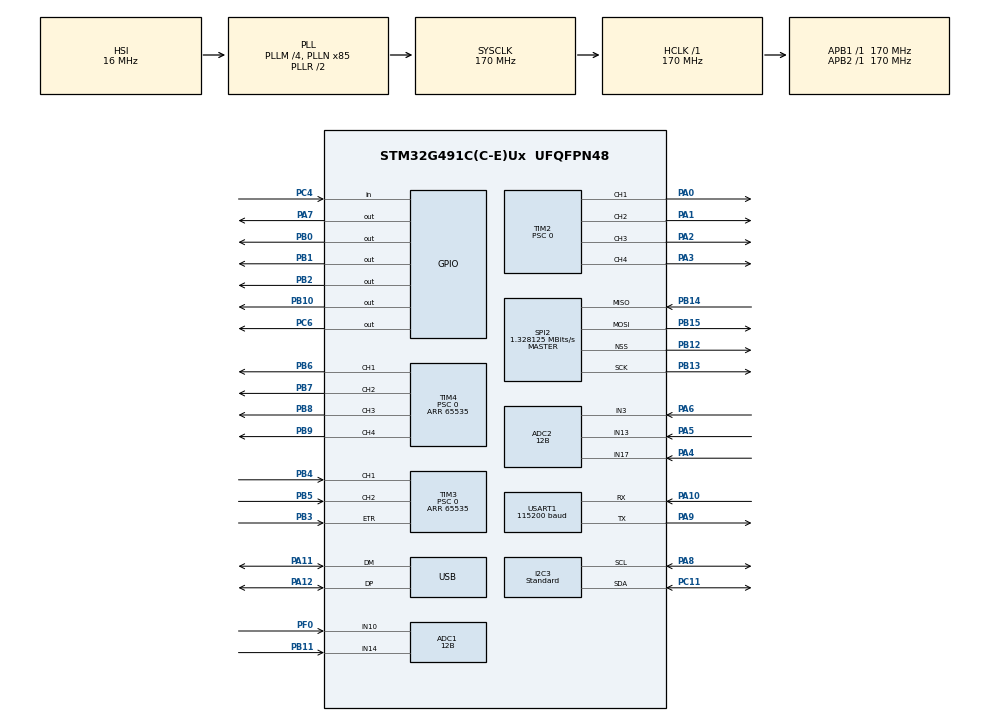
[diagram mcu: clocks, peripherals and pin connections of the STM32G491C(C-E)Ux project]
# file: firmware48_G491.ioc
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ADC1.Channel-0\#ChannelRegularConversion=ADC_CHANNEL_14
ADC1.Channel-1\#ChannelRegularConversion=ADC_CHANNEL_TEMPSENSOR_ADC1
ADC1.Channel-2\#ChannelRegularConversion=ADC_CHANNEL_VBAT
ADC1.Channel-3\#ChannelRegularConversion=ADC_CHANNEL_VREFINT
ADC1.Channel-4\#ChannelRegularConversion=ADC_CHANNEL_10
ADC1.Channel-IN=ADC_CHANNEL_VREFINT
ADC1.Channel-IN10=ADC_CHANNEL_10
ADC1.Channel-IN14=ADC_CHANNEL_14
ADC1.ClockPrescaler=ADC_CLOCK_ASYNC_DIV2
ADC1.ContinuousConvMode=ENABLE
ADC1.DMAContinuousRequests=ENABLE
ADC1.DataAlign=ADC_DATAALIGN_RIGHT
ADC1.DiscontinuousConvMode=DISABLE
ADC1.EOCSelection=ADC_EOC_SEQ_CONV
ADC1.EnableAnalogWatchDog1=false
ADC1.EnableAnalogWatchDog2=false
ADC1.EnableAnalogWatchDog3=false
ADC1.EnableInjectedConversion=DISABLE
ADC1.EnableRegularConversion=ENABLE
ADC1.ExternalTrigConv=ADC_SOFTWARE_START
ADC1.ExternalTrigConvEdge=ADC_EXTERNALTRIGCONVEDGE_NONE
ADC1.GainCompensation=0
ADC1.LowPowerAutoWait=DISABLE
ADC1.Mode=ADC_MODE_INDEPENDENT
ADC1.NbrOfConversion=5
ADC1.OffsetNumber-0\#ChannelRegularConversion=ADC_OFFSET_NONE
ADC1.OffsetNumber-1\#ChannelRegularConversion=ADC_OFFSET_NONE
ADC1.OffsetNumber-2\#ChannelRegularConversion=ADC_OFFSET_NONE
ADC1.OffsetNumber-3\#ChannelRegularConversion=ADC_OFFSET_NONE
ADC1.OffsetNumber-4\#ChannelRegularConversion=ADC_OFFSET_NONE
ADC1.Overrun=ADC_OVR_DATA_OVERWRITTEN
ADC1.OversamplingMode=ENABLE
ADC1.OversamplingStopReset=ADC_REGOVERSAMPLING_CONTINUED_MODE
ADC1.Rank-0\#ChannelRegularConversion=1
ADC1.Rank-1\#ChannelRegularConversion=2
ADC1.Rank-2\#ChannelRegularConversion=3
ADC1.Rank-3\#ChannelRegularConversion=4
ADC1.Rank-4\#ChannelRegularConversion=5
ADC1.Ratio=ADC_OVERSAMPLING_RATIO_256
ADC1.Resolution=ADC_RESOLUTION_12B
ADC1.RightBitShift=ADC_RIGHTBITSHIFT_4
ADC1.SamplingTime-0\#ChannelRegularConversion=ADC_SAMPLETIME_640CYCLES_5
ADC1.SamplingTime-1\#ChannelRegularConversion=ADC_SAMPLETIME_640CYCLES_5
ADC1.SamplingTime-2\#ChannelRegularConversion=ADC_SAMPLETIME_640CYCLES_5
ADC1.SamplingTime-3\#ChannelRegularConversion=ADC_SAMPLETIME_640CYCLES_5
ADC1.SamplingTime-4\#ChannelRegularConversion=ADC_SAMPLETIME_640CYCLES_5
ADC1.ScanConvMode=ADC_SCAN_ENABLE
ADC1.TriggeredMode=ADC_TRIGGEREDMODE_SINGLE_TRIGGER
ADC1.master=1
ADC2.Channel-0\#ChannelRegularConversion=ADC_CHANNEL_17
ADC2.Channel-1\#ChannelRegularConversion=ADC_CHANNEL_17
ADC2.Channel-2\#ChannelRegularConversion=ADC_CHANNEL_13
ADC2.Channel-3\#ChannelRegularConversion=ADC_CHANNEL_13
ADC2.Channel-4\#ChannelRegularConversion=ADC_CHANNEL_3
ADC2.Channel-5\#ChannelRegularConversion=ADC_CHANNEL_3
ADC2.Channel-IN13=ADC_CHANNEL_13
ADC2.Channel-IN17=ADC_CHANNEL_17
ADC2.Channel-IN3=ADC_CHANNEL_3
ADC2.ClockPrescaler=ADC_CLOCK_ASYNC_DIV2
ADC2.ContinuousConvMode=DISABLE
ADC2.DMAContinuousRequests=ENABLE
ADC2.DataAlign=ADC_DATAALIGN_RIGHT
ADC2.DiscontinuousConvMode=ENABLE
ADC2.EOCSelection=ADC_EOC_SEQ_CONV
ADC2.EnableAnalogWatchDog1=false
ADC2.EnableAnalogWatchDog2=false
ADC2.EnableAnalogWatchDog3=false
ADC2.EnableInjectedConversion=DISABLE
ADC2.EnableRegularConversion=ENABLE
ADC2.ExternalTrigConv=ADC_EXTERNALTRIG_T15_TRGO
ADC2.ExternalTrigConvEdge=ADC_EXTERNALTRIGCONVEDGE_RISING
ADC2.GainCompensation=0
ADC2.LowPowerAutoWait=DISABLE
ADC2.Mode=ADC_MODE_INDEPENDENT
ADC2.NbrOfConversion=6
ADC2.NbrOfDiscConversion=1
ADC2.OffsetNumber-0\#ChannelRegularConversion=ADC_OFFSET_NONE
ADC2.OffsetNumber-1\#ChannelRegularConversion=ADC_OFFSET_NONE
ADC2.OffsetNumber-2\#ChannelRegularConversion=ADC_OFFSET_NONE
ADC2.OffsetNumber-3\#ChannelRegularConversion=ADC_OFFSET_NONE
ADC2.OffsetNumber-4\#ChannelRegularConversion=ADC_OFFSET_NONE
ADC2.OffsetNumber-5\#ChannelRegularConversion=ADC_OFFSET_NONE
ADC2.Overrun=ADC_OVR_DATA_OVERWRITTEN
ADC2.OversamplingMode=ENABLE
ADC2.OversamplingStopReset=ADC_REGOVERSAMPLING_CONTINUED_MODE
ADC2.Rank-0\#ChannelRegularConversion=1
ADC2.Rank-1\#ChannelRegularConversion=2
ADC2.Rank-2\#ChannelRegularConversion=3
ADC2.Rank-3\#ChannelRegularConversion=4
ADC2.Rank-4\#ChannelRegularConversion=5
ADC2.Rank-5\#ChannelRegularConversion=6
ADC2.Ratio=ADC_OVERSAMPLING_RATIO_16
ADC2.Resolution=ADC_RESOLUTION_12B
ADC2.RightBitShift=ADC_RIGHTBITSHIFT_NONE
ADC2.SamplingTime-0\#ChannelRegularConversion=ADC_SAMPLETIME_12CYCLES_5
ADC2.SamplingTime-1\#ChannelRegularConversion=ADC_SAMPLETIME_12CYCLES_5
ADC2.SamplingTime-2\#ChannelRegularConversion=ADC_SAMPLETIME_12CYCLES_5
ADC2.SamplingTime-3\#ChannelRegularConversion=ADC_SAMPLETIME_12CYCLES_5
ADC2.SamplingTime-4\#ChannelRegularConversion=ADC_SAMPLETIME_12CYCLES_5
ADC2.SamplingTime-5\#ChannelRegularConversion=ADC_SAMPLETIME_12CYCLES_5
ADC2.ScanConvMode=ADC_SCAN_ENABLE
ADC2.TriggeredMode=ADC_TRIGGEREDMODE_SINGLE_TRIGGER
Dma.ADC1.3.Direction=DMA_PERIPH_TO_MEMORY
Dma.ADC1.3.EventEnable=DISABLE
Dma.ADC1.3.Instance=DMA1_Channel1
Dma.ADC1.3.MemDataAlignment=DMA_MDATAALIGN_HALFWORD
Dma.ADC1.3.MemInc=DMA_MINC_ENABLE
Dma.ADC1.3.Mode=DMA_CIRCULAR
Dma.ADC1.3.PeriphDataAlignment=DMA_PDATAALIGN_HALFWORD
Dma.ADC1.3.PeriphInc=DMA_PINC_DISABLE
Dma.ADC1.3.Polarity=HAL_DMAMUX_REQ_GEN_RISING
Dma.ADC1.3.Priority=DMA_PRIORITY_LOW
Dma.ADC1.3.RequestNumber=1
Dma.ADC1.3.SignalID=NONE
Dma.ADC1.3.SyncEnable=DISABLE
Dma.ADC1.3.SyncPolarity=HAL_DMAMUX_SYNC_NO_EVENT
Dma.ADC1.3.SyncRequestNumber=1
Dma.ADC1.3.SyncSignalID=NONE
Dma.ADC2.2.Direction=DMA_PERIPH_TO_MEMORY
Dma.ADC2.2.EventEnable=DISABLE
Dma.ADC2.2.Instance=DMA1_Channel2
Dma.ADC2.2.MemDataAlignment=DMA_MDATAALIGN_HALFWORD
Dma.ADC2.2.MemInc=DMA_MINC_ENABLE
Dma.ADC2.2.Mode=DMA_CIRCULAR
Dma.ADC2.2.PeriphDataAlignment=DMA_PDATAALIGN_HALFWORD
Dma.ADC2.2.PeriphInc=DMA_PINC_DISABLE
Dma.ADC2.2.Polarity=HAL_DMAMUX_REQ_GEN_RISING
Dma.ADC2.2.Priority=DMA_PRIORITY_HIGH
Dma.ADC2.2.RequestNumber=1
Dma.ADC2.2.SignalID=NONE
Dma.ADC2.2.SyncEnable=DISABLE
Dma.ADC2.2.SyncPolarity=HAL_DMAMUX_SYNC_NO_EVENT
Dma.ADC2.2.SyncRequestNumber=1
Dma.ADC2.2.SyncSignalID=NONE
Dma.Request0=SPI2_RX
Dma.Request1=SPI2_TX
Dma.Request2=ADC2
Dma.Request3=ADC1
Dma.SPI2_RX.0.Direction=DMA_PERIPH_TO_MEMORY
Dma.SPI2_RX.0.EventEnable=DISABLE
Dma.SPI2_RX.0.Instance=DMA2_Channel1
Dma.SPI2_RX.0.MemDataAlignment=DMA_MDATAALIGN_HALFWORD
Dma.SPI2_RX.0.MemInc=DMA_MINC_ENABLE
Dma.SPI2_RX.0.Mode=DMA_NORMAL
Dma.SPI2_RX.0.PeriphDataAlignment=DMA_PDATAALIGN_HALFWORD
Dma.SPI2_RX.0.PeriphInc=DMA_PINC_DISABLE
Dma.SPI2_RX.0.Polarity=HAL_DMAMUX_REQ_GEN_RISING
Dma.SPI2_RX.0.Priority=DMA_PRIORITY_LOW
Dma.SPI2_RX.0.RequestNumber=1
Dma.SPI2_RX.0.SignalID=NONE
Dma.SPI2_RX.0.SyncEnable=DISABLE
Dma.SPI2_RX.0.SyncPolarity=HAL_DMAMUX_SYNC_NO_EVENT
Dma.SPI2_RX.0.SyncRequestNumber=1
Dma.SPI2_RX.0.SyncSignalID=NONE
Dma.SPI2_TX.1.Direction=DMA_MEMORY_TO_PERIPH
Dma.SPI2_TX.1.EventEnable=DISABLE
Dma.SPI2_TX.1.Instance=DMA2_Channel2
Dma.SPI2_TX.1.MemDataAlignment=DMA_MDATAALIGN_HALFWORD
Dma.SPI2_TX.1.MemInc=DMA_MINC_ENABLE
Dma.SPI2_TX.1.Mode=DMA_NORMAL
Dma.SPI2_TX.1.PeriphDataAlignment=DMA_PDATAALIGN_HALFWORD
Dma.SPI2_TX.1.PeriphInc=DMA_PINC_DISABLE
Dma.SPI2_TX.1.Polarity=HAL_DMAMUX_REQ_GEN_RISING
Dma.SPI2_TX.1.Priority=DMA_PRIORITY_LOW
Dma.SPI2_TX.1.RequestNumber=1
Dma.SPI2_TX.1.SignalID=NONE
Dma.SPI2_TX.1.SyncEnable=DISABLE
Dma.SPI2_TX.1.SyncPolarity=HAL_DMAMUX_SYNC_NO_EVENT
Dma.SPI2_TX.1.SyncRequestNumber=1
Dma.SPI2_TX.1.SyncSignalID=NONE
I2C3.AddressingMode=I2C_ADDRESSINGMODE_7BIT
I2C3.Analog_Filter=I2C_ANALOGFILTER_ENABLE
I2C3.CustomTiming=Disabled
I2C3.DualAddressMode=I2C_DUALADDRESS_DISABLE
I2C3.GeneralCallMode=I2C_GENERALCALL_DISABLE
I2C3.I2C_Coeff_DF=0
I2C3.I2C_Fall_Time=0
I2C3.I2C_Rise_Time=0
I2C3.I2C_Speed_Mode=I2C_Standard
I2C3.NoStretchMode=I2C_NOSTRETCH_DISABLE
I2C3.OwnAddress=0
I2C3.Speed=100
I2C3.Timing=0x30A0A7FB
Mcu.Family=STM32G4
Mcu.Name=STM32G491C(C-E)Ux
Mcu.Package=UFQFPN48
NVIC.ADC1_2_IRQn=true\:0\:0\:true\:false\:true\:true\:true\:true
NVIC.DMA1_Channel1_IRQn=true\:1\:0\:true\:false\:true\:false\:true\:true
NVIC.DMA1_Channel2_IRQn=true\:1\:0\:true\:false\:true\:false\:true\:true
NVIC.DMA2_Channel1_IRQn=true\:2\:0\:true\:false\:true\:false\:true\:true
NVIC.DMA2_Channel2_IRQn=true\:2\:0\:true\:false\:true\:false\:true\:true
NVIC.FLASH_IRQn=true\:3\:0\:true\:false\:true\:true\:true\:true
NVIC.I2C3_ER_IRQn=true\:3\:0\:true\:false\:true\:true\:true\:true
NVIC.I2C3_EV_IRQn=true\:3\:0\:true\:false\:true\:true\:true\:true
NVIC.PriorityGroup=NVIC_PRIORITYGROUP_4
NVIC.SPI2_IRQn=true\:3\:0\:true\:false\:true\:true\:true\:true
NVIC.TIM1_UP_TIM16_IRQn=true\:2\:0\:true\:false\:true\:true\:true\:true
NVIC.USART1_IRQn=true\:3\:0\:true\:false\:true\:true\:true\:true
PA0.GPIO_Speed=GPIO_SPEED_FREQ_VERY_HIGH
PA0.Signal=S_TIM2_CH1
PA1.GPIO_Speed=GPIO_SPEED_FREQ_VERY_HIGH
PA1.Signal=S_TIM2_CH2
PA10.Mode=Asynchronous
PA10.Signal=USART1_RX
PA11.Mode=Device
PA11.Signal=USB_DM
PA12.Mode=Device
PA12.Signal=USB_DP
PA13.Mode=Serial_Wire
PA13.Signal=SYS_JTMS-SWDIO
PA14.Mode=Serial_Wire
PA14.Signal=SYS_JTCK-SWCLK
PA2.GPIO_Speed=GPIO_SPEED_FREQ_VERY_HIGH
PA2.Signal=S_TIM2_CH3
PA3.GPIO_Speed=GPIO_SPEED_FREQ_VERY_HIGH
PA3.Signal=S_TIM2_CH4
PA4.Mode=IN17-Single-Ended
PA4.Signal=ADC2_IN17
PA5.Mode=IN13-Single-Ended
PA5.Signal=ADC2_IN13
PA6.Mode=IN3-Single-Ended
PA6.Signal=ADC2_IN3
PA7.GPIO_Speed=GPIO_SPEED_FREQ_VERY_HIGH
PA7.Signal=GPIO_Output
PA8.GPIO_Pu=GPIO_PULLUP
PA8.Mode=I2C
PA8.Signal=I2C3_SCL
PA9.Mode=Asynchronous
PA9.Signal=USART1_TX
PB0.GPIO_Speed=GPIO_SPEED_FREQ_VERY_HIGH
PB0.Signal=GPIO_Output
PB1.GPIO_Speed=GPIO_SPEED_FREQ_VERY_HIGH
PB1.Signal=GPIO_Output
PB10.GPIO_Speed=GPIO_SPEED_FREQ_VERY_HIGH
PB10.PinState=GPIO_PIN_SET
PB10.Signal=GPIO_Output
PB11.Mode=IN14-Single-Ended
PB11.Signal=ADC1_IN14
PB12.GPIO_Speed=GPIO_SPEED_FREQ_VERY_HIGH
PB12.Mode=NSS_Signal_Hard_Output
PB12.Signal=SPI2_NSS
PB13.GPIO_Speed=GPIO_SPEED_FREQ_VERY_HIGH
PB13.Mode=Full_Duplex_Master
PB13.Signal=SPI2_SCK
PB14.GPIO_PuPd=GPIO_NOPULL
PB14.GPIO_Speed=GPIO_SPEED_FREQ_VERY_HIGH
PB14.Mode=Full_Duplex_Master
PB14.Signal=SPI2_MISO
PB15.GPIO_Speed=GPIO_SPEED_FREQ_VERY_HIGH
PB15.Mode=Full_Duplex_Master
PB15.Signal=SPI2_MOSI
PB2.GPIO_Speed=GPIO_SPEED_FREQ_VERY_HIGH
PB2.Signal=GPIO_Output
PB3.GPIO_Speed=GPIO_SPEED_FREQ_VERY_HIGH
PB3.Signal=S_TIM3_ETR
PB4.GPIO_Speed=GPIO_SPEED_FREQ_VERY_HIGH
PB4.Signal=S_TIM3_CH1
PB5.GPIO_Speed=GPIO_SPEED_FREQ_VERY_HIGH
PB5.Signal=S_TIM3_CH2
PB6.GPIO_Speed=GPIO_SPEED_FREQ_VERY_HIGH
PB6.Signal=S_TIM4_CH1
PB7.GPIO_Speed=GPIO_SPEED_FREQ_VERY_HIGH
PB7.Signal=S_TIM4_CH2
PB8-BOOT0.GPIO_Speed=GPIO_SPEED_FREQ_VERY_HIGH
PB8-BOOT0.Signal=S_TIM4_CH3
PB9.GPIO_Speed=GPIO_SPEED_FREQ_VERY_HIGH
PB9.Signal=S_TIM4_CH4
PC11.GPIO_Pu=GPIO_PULLUP
PC11.Mode=I2C
PC11.Signal=I2C3_SDA
PC4.GPIO_PuPd=GPIO_PULLUP
PC4.Signal=GPIO_Input
PC6.GPIO_Speed=GPIO_SPEED_FREQ_VERY_HIGH
PC6.PinState=GPIO_PIN_SET
PC6.Signal=GPIO_Output
PF0-OSC_IN.Mode=IN10-Single-Ended
PF0-OSC_IN.Signal=ADC1_IN10
ProjectManager.HeapSize=0x100
ProjectManager.StackSize=0x800
ProjectManager.TargetToolchain=Makefile
RCC.ADC12CLockSelection=RCC_ADC12CLKSOURCE_PLL
RCC.ADC12Freq_Value=113333333.33333333
RCC.ADC345Freq_Value=170000000
RCC.AHBFreq_Value=170000000
RCC.APB1Freq_Value=170000000
RCC.APB1TimFreq_Value=170000000
RCC.APB2Freq_Value=170000000
RCC.APB2TimFreq_Value=170000000
RCC.CortexFreq_Value=170000000
RCC.EXTERNAL_CLOCK_VALUE=12288000
RCC.FLatency=FLASH_LATENCY_4
RCC.HCLKFreq_Value=170000000
RCC.HSE_VALUE=8000000
RCC.HSI48_VALUE=48000000
RCC.HSI_VALUE=16000000
RCC.LSE_VALUE=32768
RCC.PLLM=RCC_PLLM_DIV4
RCC.PLLN=85
RCC.PLLP=RCC_PLLP_DIV3
RCC.PWR_Regulator_Voltage_Scale=PWR_REGULATOR_VOLTAGE_SCALE1_BOOST
RCC.SYSCLKFreq_VALUE=170000000
RCC.SYSCLKSource=RCC_SYSCLKSOURCE_PLLCLK
RCC.USBFreq_Value=48000000
RCC.VCOOutputFreq_Value=340000000
SH.S_TIM2_CH1.0=TIM2_CH1,PWM Generation1 CH1
SH.S_TIM2_CH2.0=TIM2_CH2,PWM Generation2 CH2
SH.S_TIM2_CH3.0=TIM2_CH3,PWM Generation3 CH3
SH.S_TIM2_CH4.0=TIM2_CH4,PWM Generation4 CH4
SH.S_TIM3_CH1.0=TIM3_CH1,Encoder_Interface_w_index
SH.S_TIM3_CH2.0=TIM3_CH2,Encoder_Interface_w_index
SH.S_TIM3_ETR.0=TIM3_ETR,Encoder_Interface_w_index
SH.S_TIM4_CH1.0=TIM4_CH1,PWM Generation1 CH1
SH.S_TIM4_CH2.0=TIM4_CH2,PWM Generation2 CH2
SH.S_TIM4_CH3.0=TIM4_CH3,PWM Generation3 CH3
SH.S_TIM4_CH4.0=TIM4_CH4,PWM Generation4 CH4
SPI2.BaudRatePrescaler=SPI_BAUDRATEPRESCALER_128
SPI2.CLKPhase=SPI_PHASE_2EDGE
SPI2.CLKPolarity=SPI_POLARITY_LOW
SPI2.CRCCalculation=SPI_CRCCALCULATION_DISABLE
SPI2.CalculateBaudRate=1.328125 MBits/s
SPI2.DataSize=SPI_DATASIZE_16BIT
SPI2.Direction=SPI_DIRECTION_2LINES
SPI2.FirstBit=SPI_FIRSTBIT_MSB
SPI2.Mode=SPI_MODE_MASTER
SPI2.NSS=SPI_NSS_HARD_OUTPUT
SPI2.TIMode=SPI_TIMODE_DISABLE
SPI2.VirtualNSS=VM_NSSHARD
SPI2.VirtualType=VM_MASTER
SYS.Mode=PWR_PVD_MODE_NORMAL
SYS.PVDLevel=PWR_PVDLEVEL_0
TIM1.AutoReloadPreload=TIM_AUTORELOAD_PRELOAD_DISABLE
TIM1.ClockDivision=TIM_CLOCKDIVISION_DIV1
TIM1.CounterMode=TIM_COUNTERMODE_UP
TIM1.Dithering=Disable
TIM1.PeriodNoDither=0xffff
TIM1.Prescaler=0
TIM1.RepetitionCounter=0
TIM1.TIM_MasterOutputTrigger=TIM_TRGO_RESET
TIM1.TIM_MasterOutputTrigger2=TIM_TRGO2_RESET
TIM1.TIM_MasterSlaveMode=TIM_MASTERSLAVEMODE_DISABLE
TIM1.TIM_SlaveMode=TIM_SLAVEMODE_GATED
TIM15.AutoReloadPreload=TIM_AUTORELOAD_PRELOAD_DISABLE
TIM15.AutomaticOutput=TIM_AUTOMATICOUTPUT_DISABLE
TIM15.BreakFilter=0
TIM15.BreakPolarity=TIM_BREAKPOLARITY_HIGH
TIM15.BreakState=TIM_BREAK_DISABLE
TIM15.Channel-Output\ Compare1\ No\ Output=TIM_CHANNEL_1
TIM15.ClockDivision=TIM_CLOCKDIVISION_DIV1
TIM15.CounterMode=TIM_COUNTERMODE_UP
TIM15.Dithering=Disable
TIM15.LockLevel=TIM_LOCKLEVEL_OFF
TIM15.OC1Preload=ENABLE
TIM15.OCIdleState_1=TIM_OCIDLESTATE_RESET
TIM15.OCMode_1=TIM_OCMODE_ACTIVE
TIM15.OCPolarity_1=TIM_OCPOLARITY_HIGH
TIM15.OffStateIDLEMode=TIM_OSSI_DISABLE
TIM15.OffStateRunMode=TIM_OSSR_DISABLE
TIM15.PeriodNoDither=1699
TIM15.Prescaler=0
TIM15.PulseNoDither_1=1099
TIM15.RepetitionCounter=0
TIM15.SourceBRKCOMP1=TIM_BREAKINPUTSOURCE_DISABLE
TIM15.SourceBRKCOMP2=TIM_BREAKINPUTSOURCE_DISABLE
TIM15.SourceBRKCOMP3=TIM_BREAKINPUTSOURCE_DISABLE
TIM15.SourceBRKCOMP4=TIM_BREAKINPUTSOURCE_DISABLE
TIM15.SourceBRKDigInput=TIM_BREAKINPUTSOURCE_DISABLE
TIM15.TIM_MasterOutputTrigger=TIM_TRGO_OC1
TIM15.TIM_MasterSlaveMode=TIM_MASTERSLAVEMODE_DISABLE
TIM15.TIM_SlaveMode=TIM_SLAVEMODE_COMBINED_RESETTRIGGER
TIM16.AutoReloadPreload=TIM_AUTORELOAD_PRELOAD_DISABLE
TIM16.AutomaticOutput=TIM_AUTOMATICOUTPUT_DISABLE
TIM16.BreakFilter=0
TIM16.BreakPolarity=TIM_BREAKPOLARITY_HIGH
TIM16.BreakState=TIM_BREAK_DISABLE
TIM16.Channel=TIM_CHANNEL_1
TIM16.ClockDivision=TIM_CLOCKDIVISION_DIV1
TIM16.CounterMode=TIM_COUNTERMODE_UP
TIM16.Dithering=Disable
TIM16.LockLevel=TIM_LOCKLEVEL_OFF
TIM16.OC1Preload=ENABLE
TIM16.OCIdleState_1=TIM_OCIDLESTATE_RESET
TIM16.OCMode_1=TIM_OCMODE_TIMING
TIM16.OCPolarity_1=TIM_OCPOLARITY_HIGH
TIM16.OffStateIDLEMode=TIM_OSSI_DISABLE
TIM16.OffStateRunMode=TIM_OSSR_DISABLE
TIM16.PeriodNoDither=1699
TIM16.Prescaler=0
TIM16.PulseNoDither_1=0xffff
TIM16.RepetitionCounter=0
TIM16.SourceBRKCOMP1=TIM_BREAKINPUTSOURCE_DISABLE
TIM16.SourceBRKCOMP2=TIM_BREAKINPUTSOURCE_DISABLE
TIM16.SourceBRKCOMP3=TIM_BREAKINPUTSOURCE_DISABLE
TIM16.SourceBRKCOMP4=TIM_BREAKINPUTSOURCE_DISABLE
TIM16.SourceBRKDigInput=TIM_BREAKINPUTSOURCE_DISABLE
TIM2.AutoReloadPreload=TIM_AUTORELOAD_PRELOAD_DISABLE
TIM2.Channel-PWM\ Generation1\ CH1=TIM_CHANNEL_1
TIM2.Channel-PWM\ Generation2\ CH2=TIM_CHANNEL_2
TIM2.Channel-PWM\ Generation3\ CH3=TIM_CHANNEL_3
TIM2.Channel-PWM\ Generation4\ CH4=TIM_CHANNEL_4
TIM2.ClearInputSource=TIM_CLEARINPUTSOURCE_NONE
TIM2.ClockDivision=TIM_CLOCKDIVISION_DIV1
TIM2.CounterMode=TIM_COUNTERMODE_CENTERALIGNED3
TIM2.Dithering=Enable
TIM2.Fractionnal_PeriodDither=15
TIM2.Fractionnal_PulseDither_1=0
TIM2.Fractionnal_PulseDither_2=0
TIM2.Fractionnal_PulseDither_3=0
TIM2.Fractionnal_PulseDither_4=0
TIM2.Integer_PeriodDither=1699
TIM2.Integer_PulseDither_1=0
TIM2.Integer_PulseDither_2=0
TIM2.Integer_PulseDither_3=0
TIM2.Integer_PulseDither_4=0
TIM2.OC1Preload_PWM=ENABLE
TIM2.OC2Preload_PWM=ENABLE
TIM2.OC3Preload_PWM=ENABLE
TIM2.OC4Preload_PWM=ENABLE
TIM2.OCFastMode_PWM-PWM\ Generation1\ CH1=TIM_OCFAST_DISABLE
TIM2.OCFastMode_PWM-PWM\ Generation2\ CH2=TIM_OCFAST_DISABLE
TIM2.OCFastMode_PWM-PWM\ Generation3\ CH3=TIM_OCFAST_DISABLE
TIM2.OCFastMode_PWM-PWM\ Generation4\ CH4=TIM_OCFAST_DISABLE
TIM2.OCMode_PWM-PWM\ Generation1\ CH1=TIM_OCMODE_PWM1
TIM2.OCMode_PWM-PWM\ Generation2\ CH2=TIM_OCMODE_PWM1
TIM2.OCMode_PWM-PWM\ Generation3\ CH3=TIM_OCMODE_PWM1
TIM2.OCMode_PWM-PWM\ Generation4\ CH4=TIM_OCMODE_PWM1
TIM2.OCPolarity_1=TIM_OCPOLARITY_HIGH
TIM2.OCPolarity_2=TIM_OCPOLARITY_HIGH
TIM2.OCPolarity_3=TIM_OCPOLARITY_HIGH
TIM2.OCPolarity_4=TIM_OCPOLARITY_HIGH
TIM2.Prescaler=0
TIM2.TIM_MasterOutputTrigger=TIM_TRGO_UPDATE
TIM2.TIM_MasterSlaveMode=TIM_MASTERSLAVEMODE_DISABLE
TIM3.AutoReloadPreload=TIM_AUTORELOAD_PRELOAD_DISABLE
TIM3.ClockDivision=TIM_CLOCKDIVISION_DIV1
TIM3.CounterMode=TIM_COUNTERMODE_UP
TIM3.Dithering=Disable
TIM3.EncoderMode=TIM_ENCODERMODE_TI1
TIM3.FirstIndexEnable=DISABLE
TIM3.IC1Filter=0
TIM3.IC1Polarity=TIM_ICPOLARITY_RISING
TIM3.IC1Prescaler=TIM_ICPSC_DIV1
TIM3.IC1Selection=TIM_ICSELECTION_DIRECTTI
TIM3.IC2Filter=0
TIM3.IC2Polarity=TIM_ICPOLARITY_RISING
TIM3.IC2Prescaler=TIM_ICPSC_DIV1
TIM3.IC2Selection=TIM_ICSELECTION_DIRECTTI
TIM3.IndexDirection=TIM_ENCODERINDEX_DIRECTION_UP_DOWN
TIM3.IndexFilter=0
TIM3.IndexPolarity=TIM_ENCODERINDEX_POLARITY_NONINVERTED
TIM3.IndexPosition=TIM_ENCODERINDEX_POSITION_00
TIM3.IndexPrescaler=TIM_ENCODERINDEX_PRESCALER_DIV1
TIM3.PeriodNoDither=65535
TIM3.Prescaler=0
TIM3.SMS_Preload_Activation=DISABLE
TIM3.TIM_MasterOutputTrigger=TIM_TRGO_RESET
TIM3.TIM_MasterSlaveMode=TIM_MASTERSLAVEMODE_DISABLE
TIM4.AutoReloadPreload=TIM_AUTORELOAD_PRELOAD_DISABLE
TIM4.Channel-PWM\ Generation1\ CH1=TIM_CHANNEL_1
TIM4.Channel-PWM\ Generation2\ CH2=TIM_CHANNEL_2
TIM4.Channel-PWM\ Generation3\ CH3=TIM_CHANNEL_3
TIM4.Channel-PWM\ Generation4\ CH4=TIM_CHANNEL_4
TIM4.ClearInputSource=TIM_CLEARINPUTSOURCE_NONE
TIM4.ClockDivision=TIM_CLOCKDIVISION_DIV1
TIM4.CounterMode=TIM_COUNTERMODE_UP
TIM4.Dithering=Disable
TIM4.OC1Preload_PWM=ENABLE
TIM4.OC2Preload_PWM=ENABLE
TIM4.OC3Preload_PWM=ENABLE
TIM4.OC4Preload_PWM=ENABLE
TIM4.OCFastMode_PWM-PWM\ Generation1\ CH1=TIM_OCFAST_DISABLE
TIM4.OCFastMode_PWM-PWM\ Generation2\ CH2=TIM_OCFAST_DISABLE
TIM4.OCFastMode_PWM-PWM\ Generation3\ CH3=TIM_OCFAST_DISABLE
TIM4.OCFastMode_PWM-PWM\ Generation4\ CH4=TIM_OCFAST_DISABLE
TIM4.OCMode_PWM-PWM\ Generation1\ CH1=TIM_OCMODE_PWM1
TIM4.OCMode_PWM-PWM\ Generation2\ CH2=TIM_OCMODE_PWM1
TIM4.OCMode_PWM-PWM\ Generation3\ CH3=TIM_OCMODE_PWM1
TIM4.OCMode_PWM-PWM\ Generation4\ CH4=TIM_OCMODE_PWM1
TIM4.OCPolarity_1=TIM_OCPOLARITY_HIGH
TIM4.OCPolarity_2=TIM_OCPOLARITY_HIGH
TIM4.OCPolarity_3=TIM_OCPOLARITY_HIGH
TIM4.OCPolarity_4=TIM_OCPOLARITY_HIGH
TIM4.PeriodNoDither=65535
TIM4.Prescaler=0
TIM4.PulseNoDither_1=0
TIM4.PulseNoDither_2=0
TIM4.PulseNoDither_3=0
TIM4.PulseNoDither_4=0
TIM4.TIM_MasterOutputTrigger=TIM_TRGO_RESET
TIM4.TIM_MasterSlaveMode=TIM_MASTERSLAVEMODE_DISABLE
TIM6.AutoReloadPreload=TIM_AUTORELOAD_PRELOAD_DISABLE
TIM6.CounterMode=TIM_COUNTERMODE_UP
TIM6.Dithering=Disable
TIM6.PeriodNoDither=65535
TIM6.Prescaler=169
TIM6.TIM_MasterOutputTrigger=TIM_TRGO_RESET
USART1.AutoBaudRateEnableParam=UART_ADVFEATURE_AUTOBAUDRATE_DISABLE
USART1.BaudRate=115200
USART1.ClockPrescaler=PRESCALER_DIV1
USART1.DMADisableonRxErrorParam=ADVFEATURE_DMA_ENABLEONRXERROR
USART1.DataInvertParam=ADVFEATURE_DATAINV_DISABLE
USART1.FIFOMode=FIFOMODE_DISABLE
USART1.MSBFirstParam=ADVFEATURE_MSBFIRST_DISABLE
USART1.Mode=MODE_TX_RX
USART1.OneBitSampling=UART_ONE_BIT_SAMPLE_DISABLE
USART1.OverSampling=UART_OVERSAMPLING_16
USART1.OverrunDisableParam=ADVFEATURE_OVERRUN_ENABLE
USART1.Parity=PARITY_NONE
USART1.RXFIFOThreshold=RXFIFO_THRESHOLD_1EIGHTHFULL
USART1.RxPinLevelInvertParam=ADVFEATURE_RXINV_DISABLE
USART1.StopBits=STOPBITS_1
USART1.SwapParam=ADVFEATURE_SWAP_DISABLE
USART1.TXFIFOThreshold=TXFIFO_THRESHOLD_1EIGHTHFULL
USART1.TxPinLevelInvertParam=ADVFEATURE_TXINV_DISABLE
USART1.VirtualMode-Asynchronous=VM_ASYNC
USART1.WordLength=WORDLENGTH_8B
USB.DeviceSpeed=PCD_SPEED_FULL
USB.Sof_enable=ENABLE
USB.battery_charging_enable=DISABLE
USB.low_power_enable=DISABLE
USB.lpm_enable=ENABLE
USB.phy_itface=PCD_PHY_EMBEDDED
VP_ADC1_TempSens_Input.Mode=IN-TempSens
VP_ADC1_Vbat_Input.Mode=IN-Vbat
VP_ADC1_Vref_Input.Mode=IN-Vrefint
VP_CORDIC_VS_CORDIC.Mode=CORDIC_Activate
VP_RCC_VS_USB.Mode=USB_FS
VP_SYS_VS_DBSignals.Mode=DisableDeadBatterySignals
VP_SYS_V_PVD_IN.Mode=Mode_PVD_Int
VP_TIM15_VS_ClockSourceINT.Mode=Internal
VP_TIM15_VS_ClockSourceITR.Mode=TriggerSource_ITR1
VP_TIM15_VS_ControllerModeCombinedResetTrigger.Mode=Combined_Reset_Trigger_Mode
VP_TIM15_VS_OPM.Mode=OPM_bit
VP_TIM15_VS_no_output1.Mode=Output Compare1 No Output
VP_TIM16_VS_ClockSourceINT.Mode=Enable_Timer
VP_TIM16_VS_OPM.Mode=OPM_bit
VP_TIM16_VS_no_output1.Mode=Output Compare1 No Output
VP_TIM1_VS_ClockSourceINT.Mode=Internal
VP_TIM1_VS_ClockSourceITR.Mode=TriggerSource_ITR1
VP_TIM1_VS_ControllerModeGated.Mode=Gated Mode
VP_TIM2_VS_ClockSourceINT.Mode=Internal
VP_TIM4_VS_ClockSourceINT.Mode=Internal
VP_TIM6_VS_ClockSourceINT.Mode=Enable_Timer
board=custom

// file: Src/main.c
/* USER CODE BEGIN Header */
/**
	******************************************************************************
	* @file           : main.c
	* @brief          : Main program body
	******************************************************************************
	* @attention
	*
	* <h2><center>&copy; Copyright (c) 2019 STMicroelectronics.
	* All rights reserved.</center></h2>
	*
	* This software component is licensed by ST under BSD 3-Clause license,
	* the "License"; You may not use this file except in compliance with the
	* License. You may obtain a copy of the License at:
	*                        opensource.org/licenses/BSD-3-Clause
	*
	******************************************************************************
	*/
/* USER CODE END Header */
#include "main.h"

/* USER CODE BEGIN Includes */

#include "ssf_main.h"
#include "usb_device.h"

/* USER CODE END Includes */

ADC_HandleTypeDef hadc1;
ADC_HandleTypeDef hadc2;
DMA_HandleTypeDef hdma_adc1;
DMA_HandleTypeDef hdma_adc2;

CORDIC_HandleTypeDef hcordic;

I2C_HandleTypeDef hi2c3;

SPI_HandleTypeDef hspi2;
DMA_HandleTypeDef hdma_spi2_rx;
DMA_HandleTypeDef hdma_spi2_tx;

TIM_HandleTypeDef htim1;
TIM_HandleTypeDef htim2;
TIM_HandleTypeDef htim3;
TIM_HandleTypeDef htim4;
TIM_HandleTypeDef htim6;
TIM_HandleTypeDef htim15;
TIM_HandleTypeDef htim16;

UART_HandleTypeDef huart1;

PCD_HandleTypeDef hpcd_USB_FS;

void SystemClock_Config(void);
static void MX_GPIO_Init(void);
static void MX_DMA_Init(void);
static void MX_ADC1_Init(void);
static void MX_ADC2_Init(void);
static void MX_I2C3_Init(void);
static void MX_SPI2_Init(void);
static void MX_TIM2_Init(void);
static void MX_TIM3_Init(void);
static void MX_TIM4_Init(void);
static void MX_USART1_UART_Init(void);
static void MX_TIM6_Init(void);
static void MX_CORDIC_Init(void);
static void MX_USB_PCD_Init(void);
static void MX_TIM15_Init(void);
static void MX_TIM1_Init(void);
static void MX_TIM16_Init(void);

int main(void)
{

  /* MCU Configuration--------------------------------------------------------*/

  /* Reset of all peripherals, Initializes the Flash interface and the Systick. */
  HAL_Init();

  /* Configure the system clock */
  SystemClock_Config();

  /* Initialize all configured peripherals */
  MX_GPIO_Init();
  MX_DMA_Init();
  MX_ADC1_Init();
  MX_ADC2_Init();
  MX_I2C3_Init();
  MX_SPI2_Init();
  MX_TIM2_Init();
  MX_TIM3_Init();
  MX_TIM4_Init();
  MX_USART1_UART_Init();
  MX_TIM6_Init();
  MX_CORDIC_Init();
  MX_USB_PCD_Init();
  MX_TIM15_Init();
  MX_TIM1_Init();
  MX_TIM16_Init();
  /* USER CODE BEGIN 2 */

  HAL_USBD_Setup();

  UsbDevice_Init();

  ssf_init();

  /* USER CODE END 2 */

  /* Infinite loop */
  /* USER CODE BEGIN WHILE */
	while (1)
	{

		ssf_idle();
    /* USER CODE END WHILE */

	}
}

void SystemClock_Config(void)
{
  RCC_OscInitTypeDef RCC_OscInitStruct = {0};
  RCC_ClkInitTypeDef RCC_ClkInitStruct = {0};
  RCC_CRSInitTypeDef pInit = {0};

  /** Configure the main internal regulator output voltage
  */
  HAL_PWREx_ControlVoltageScaling(PWR_REGULATOR_VOLTAGE_SCALE1_BOOST);

  /** Initializes the RCC Oscillators according to the specified parameters
  * in the RCC_OscInitTypeDef structure.
  */
  RCC_OscInitStruct.OscillatorType = RCC_OSCILLATORTYPE_HSI|RCC_OSCILLATORTYPE_HSI48;
  RCC_OscInitStruct.HSIState = RCC_HSI_ON;
  RCC_OscInitStruct.HSICalibrationValue = RCC_HSICALIBRATION_DEFAULT;
  RCC_OscInitStruct.HSI48State = RCC_HSI48_ON;
  RCC_OscInitStruct.PLL.PLLState = RCC_PLL_ON;
  RCC_OscInitStruct.PLL.PLLSource = RCC_PLLSOURCE_HSI;
  RCC_OscInitStruct.PLL.PLLM = RCC_PLLM_DIV4;
  RCC_OscInitStruct.PLL.PLLN = 85;
  RCC_OscInitStruct.PLL.PLLP = RCC_PLLP_DIV3;
  RCC_OscInitStruct.PLL.PLLQ = RCC_PLLQ_DIV2;
  RCC_OscInitStruct.PLL.PLLR = RCC_PLLR_DIV2;
  if (HAL_RCC_OscConfig(&RCC_OscInitStruct) != HAL_OK)
  {
    Error_Handler();
  }

  /** Initializes the CPU, AHB and APB buses clocks
  */
  RCC_ClkInitStruct.ClockType = RCC_CLOCKTYPE_HCLK|RCC_CLOCKTYPE_SYSCLK
                              |RCC_CLOCKTYPE_PCLK1|RCC_CLOCKTYPE_PCLK2;
  RCC_ClkInitStruct.SYSCLKSource = RCC_SYSCLKSOURCE_PLLCLK;
  RCC_ClkInitStruct.AHBCLKDivider = RCC_SYSCLK_DIV1;
  RCC_ClkInitStruct.APB1CLKDivider = RCC_HCLK_DIV1;
  RCC_ClkInitStruct.APB2CLKDivider = RCC_HCLK_DIV1;

  if (HAL_RCC_ClockConfig(&RCC_ClkInitStruct, FLASH_LATENCY_4) != HAL_OK)
  {
    Error_Handler();
  }

  /** Enable the SYSCFG APB clock
  */
  __HAL_RCC_CRS_CLK_ENABLE();

  /** Configures CRS
  */
  pInit.Prescaler = RCC_CRS_SYNC_DIV1;
  pInit.Source = RCC_CRS_SYNC_SOURCE_USB;
  pInit.Polarity = RCC_CRS_SYNC_POLARITY_RISING;
  pInit.ReloadValue = __HAL_RCC_CRS_RELOADVALUE_CALCULATE(48000000,1000);
  pInit.ErrorLimitValue = 34;
  pInit.HSI48CalibrationValue = 32;

  HAL_RCCEx_CRSConfig(&pInit);
}

static void MX_ADC1_Init(void)
{

  ADC_MultiModeTypeDef multimode = {0};
  ADC_ChannelConfTypeDef sConfig = {0};

  /** Common config
  */
  hadc1.Instance = ADC1;
  hadc1.Init.ClockPrescaler = ADC_CLOCK_ASYNC_DIV2;
  hadc1.Init.Resolution = ADC_RESOLUTION_12B;
  hadc1.Init.DataAlign = ADC_DATAALIGN_RIGHT;
  hadc1.Init.GainCompensation = 0;
  hadc1.Init.ScanConvMode = ADC_SCAN_ENABLE;
  hadc1.Init.EOCSelection = ADC_EOC_SEQ_CONV;
  hadc1.Init.LowPowerAutoWait = DISABLE;
  hadc1.Init.ContinuousConvMode = ENABLE;
  hadc1.Init.NbrOfConversion = 5;
  hadc1.Init.DiscontinuousConvMode = DISABLE;
  hadc1.Init.ExternalTrigConv = ADC_SOFTWARE_START;
  hadc1.Init.ExternalTrigConvEdge = ADC_EXTERNALTRIGCONVEDGE_NONE;
  hadc1.Init.DMAContinuousRequests = ENABLE;
  hadc1.Init.Overrun = ADC_OVR_DATA_OVERWRITTEN;
  hadc1.Init.OversamplingMode = ENABLE;
  hadc1.Init.Oversampling.Ratio = ADC_OVERSAMPLING_RATIO_256;
  hadc1.Init.Oversampling.RightBitShift = ADC_RIGHTBITSHIFT_4;
  hadc1.Init.Oversampling.TriggeredMode = ADC_TRIGGEREDMODE_SINGLE_TRIGGER;
  hadc1.Init.Oversampling.OversamplingStopReset = ADC_REGOVERSAMPLING_CONTINUED_MODE;
  if (HAL_ADC_Init(&hadc1) != HAL_OK)
  {
    Error_Handler();
  }

  /** Configure the ADC multi-mode
  */
  multimode.Mode = ADC_MODE_INDEPENDENT;
  if (HAL_ADCEx_MultiModeConfigChannel(&hadc1, &multimode) != HAL_OK)
  {
    Error_Handler();
  }

  /** Configure Regular Channel
  */
  sConfig.Channel = ADC_CHANNEL_14;
  sConfig.Rank = ADC_REGULAR_RANK_1;
  sConfig.SamplingTime = ADC_SAMPLETIME_640CYCLES_5;
  sConfig.SingleDiff = ADC_SINGLE_ENDED;
  sConfig.OffsetNumber = ADC_OFFSET_NONE;
  sConfig.Offset = 0;
  if (HAL_ADC_ConfigChannel(&hadc1, &sConfig) != HAL_OK)
  {
    Error_Handler();
  }

  /** Configure Regular Channel
  */
  sConfig.Channel = ADC_CHANNEL_TEMPSENSOR_ADC1;
  sConfig.Rank = ADC_REGULAR_RANK_2;
  if (HAL_ADC_ConfigChannel(&hadc1, &sConfig) != HAL_OK)
  {
    Error_Handler();
  }

  /** Configure Regular Channel
  */
  sConfig.Channel = ADC_CHANNEL_VBAT;
  sConfig.Rank = ADC_REGULAR_RANK_3;
  if (HAL_ADC_ConfigChannel(&hadc1, &sConfig) != HAL_OK)
  {
    Error_Handler();
  }

  /** Configure Regular Channel
  */
  sConfig.Channel = ADC_CHANNEL_VREFINT;
  sConfig.Rank = ADC_REGULAR_RANK_4;
  if (HAL_ADC_ConfigChannel(&hadc1, &sConfig) != HAL_OK)
  {
    Error_Handler();
  }

  /** Configure Regular Channel
  */
  sConfig.Channel = ADC_CHANNEL_10;
  sConfig.Rank = ADC_REGULAR_RANK_5;
  if (HAL_ADC_ConfigChannel(&hadc1, &sConfig) != HAL_OK)
  {
    Error_Handler();
  }

}

static void MX_ADC2_Init(void)
{

  ADC_ChannelConfTypeDef sConfig = {0};

  /** Common config
  */
  hadc2.Instance = ADC2;
  hadc2.Init.ClockPrescaler = ADC_CLOCK_ASYNC_DIV2;
  hadc2.Init.Resolution = ADC_RESOLUTION_12B;
  hadc2.Init.DataAlign = ADC_DATAALIGN_RIGHT;
  hadc2.Init.GainCompensation = 0;
  hadc2.Init.ScanConvMode = ADC_SCAN_ENABLE;
  hadc2.Init.EOCSelection = ADC_EOC_SEQ_CONV;
  hadc2.Init.LowPowerAutoWait = DISABLE;
  hadc2.Init.ContinuousConvMode = DISABLE;
  hadc2.Init.NbrOfConversion = 6;
  hadc2.Init.DiscontinuousConvMode = ENABLE;
  hadc2.Init.NbrOfDiscConversion = 1;
  hadc2.Init.ExternalTrigConv = ADC_EXTERNALTRIG_T15_TRGO;
  hadc2.Init.ExternalTrigConvEdge = ADC_EXTERNALTRIGCONVEDGE_RISING;
  hadc2.Init.DMAContinuousRequests = ENABLE;
  hadc2.Init.Overrun = ADC_OVR_DATA_OVERWRITTEN;
  hadc2.Init.OversamplingMode = ENABLE;
  hadc2.Init.Oversampling.Ratio = ADC_OVERSAMPLING_RATIO_16;
  hadc2.Init.Oversampling.RightBitShift = ADC_RIGHTBITSHIFT_NONE;
  hadc2.Init.Oversampling.TriggeredMode = ADC_TRIGGEREDMODE_SINGLE_TRIGGER;
  hadc2.Init.Oversampling.OversamplingStopReset = ADC_REGOVERSAMPLING_CONTINUED_MODE;
  if (HAL_ADC_Init(&hadc2) != HAL_OK)
  {
    Error_Handler();
  }

  /** Configure Regular Channel
  */
  sConfig.Channel = ADC_CHANNEL_17;
  sConfig.Rank = ADC_REGULAR_RANK_1;
  sConfig.SamplingTime = ADC_SAMPLETIME_12CYCLES_5;
  sConfig.SingleDiff = ADC_SINGLE_ENDED;
  sConfig.OffsetNumber = ADC_OFFSET_NONE;
  sConfig.Offset = 0;
  if (HAL_ADC_ConfigChannel(&hadc2, &sConfig) != HAL_OK)
  {
    Error_Handler();
  }

  /** Configure Regular Channel
  */
  sConfig.Rank = ADC_REGULAR_RANK_2;
  if (HAL_ADC_ConfigChannel(&hadc2, &sConfig) != HAL_OK)
  {
    Error_Handler();
  }

  /** Configure Regular Channel
  */
  sConfig.Channel = ADC_CHANNEL_13;
  sConfig.Rank = ADC_REGULAR_RANK_3;
  if (HAL_ADC_ConfigChannel(&hadc2, &sConfig) != HAL_OK)
  {
    Error_Handler();
  }

  /** Configure Regular Channel
  */
  sConfig.Rank = ADC_REGULAR_RANK_4;
  if (HAL_ADC_ConfigChannel(&hadc2, &sConfig) != HAL_OK)
  {
    Error_Handler();
  }

  /** Configure Regular Channel
  */
  sConfig.Channel = ADC_CHANNEL_3;
  sConfig.Rank = ADC_REGULAR_RANK_5;
  if (HAL_ADC_ConfigChannel(&hadc2, &sConfig) != HAL_OK)
  {
    Error_Handler();
  }

  /** Configure Regular Channel
  */
  sConfig.Rank = ADC_REGULAR_RANK_6;
  if (HAL_ADC_ConfigChannel(&hadc2, &sConfig) != HAL_OK)
  {
    Error_Handler();
  }

}

static void MX_CORDIC_Init(void)
{

  hcordic.Instance = CORDIC;
  if (HAL_CORDIC_Init(&hcordic) != HAL_OK)
  {
    Error_Handler();
  }

}

static void MX_I2C3_Init(void)
{

  hi2c3.Instance = I2C3;
  hi2c3.Init.Timing = 0x30A0A7FB;
  hi2c3.Init.OwnAddress1 = 0;
  hi2c3.Init.AddressingMode = I2C_ADDRESSINGMODE_7BIT;
  hi2c3.Init.DualAddressMode = I2C_DUALADDRESS_DISABLE;
  hi2c3.Init.OwnAddress2 = 0;
  hi2c3.Init.OwnAddress2Masks = I2C_OA2_NOMASK;
  hi2c3.Init.GeneralCallMode = I2C_GENERALCALL_DISABLE;
  hi2c3.Init.NoStretchMode = I2C_NOSTRETCH_DISABLE;
  if (HAL_I2C_Init(&hi2c3) != HAL_OK)
  {
    Error_Handler();
  }

  /** Configure Analogue filter
  */
  if (HAL_I2CEx_ConfigAnalogFilter(&hi2c3, I2C_ANALOGFILTER_ENABLE) != HAL_OK)
  {
    Error_Handler();
  }

  /** Configure Digital filter
  */
  if (HAL_I2CEx_ConfigDigitalFilter(&hi2c3, 0) != HAL_OK)
  {
    Error_Handler();
  }

}

static void MX_SPI2_Init(void)
{

  /* SPI2 parameter configuration*/
  hspi2.Instance = SPI2;
  hspi2.Init.Mode = SPI_MODE_MASTER;
  hspi2.Init.Direction = SPI_DIRECTION_2LINES;
  hspi2.Init.DataSize = SPI_DATASIZE_16BIT;
  hspi2.Init.CLKPolarity = SPI_POLARITY_LOW;
  hspi2.Init.CLKPhase = SPI_PHASE_2EDGE;
  hspi2.Init.NSS = SPI_NSS_HARD_OUTPUT;
  hspi2.Init.BaudRatePrescaler = SPI_BAUDRATEPRESCALER_128;
  hspi2.Init.FirstBit = SPI_FIRSTBIT_MSB;
  hspi2.Init.TIMode = SPI_TIMODE_DISABLE;
  hspi2.Init.CRCCalculation = SPI_CRCCALCULATION_DISABLE;
  hspi2.Init.CRCPolynomial = 7;
  hspi2.Init.CRCLength = SPI_CRC_LENGTH_DATASIZE;
  hspi2.Init.NSSPMode = SPI_NSS_PULSE_DISABLE;
  if (HAL_SPI_Init(&hspi2) != HAL_OK)
  {
    Error_Handler();
  }

}

static void MX_TIM1_Init(void)
{

  TIM_ClockConfigTypeDef sClockSourceConfig = {0};
  TIM_SlaveConfigTypeDef sSlaveConfig = {0};
  TIM_MasterConfigTypeDef sMasterConfig = {0};

  htim1.Instance = TIM1;
  htim1.Init.Prescaler = 0;
  htim1.Init.CounterMode = TIM_COUNTERMODE_UP;
  htim1.Init.Period = 65535;
  htim1.Init.ClockDivision = TIM_CLOCKDIVISION_DIV1;
  htim1.Init.RepetitionCounter = 0;
  htim1.Init.AutoReloadPreload = TIM_AUTORELOAD_PRELOAD_DISABLE;
  if (HAL_TIM_Base_Init(&htim1) != HAL_OK)
  {
    Error_Handler();
  }
  sClockSourceConfig.ClockSource = TIM_CLOCKSOURCE_INTERNAL;
  if (HAL_TIM_ConfigClockSource(&htim1, &sClockSourceConfig) != HAL_OK)
  {
    Error_Handler();
  }
  sSlaveConfig.SlaveMode = TIM_SLAVEMODE_GATED;
  sSlaveConfig.InputTrigger = TIM_TS_ITR1;
  if (HAL_TIM_SlaveConfigSynchro(&htim1, &sSlaveConfig) != HAL_OK)
  {
    Error_Handler();
  }
  sMasterConfig.MasterOutputTrigger = TIM_TRGO_RESET;
  sMasterConfig.MasterOutputTrigger2 = TIM_TRGO2_RESET;
  sMasterConfig.MasterSlaveMode = TIM_MASTERSLAVEMODE_DISABLE;
  if (HAL_TIMEx_MasterConfigSynchronization(&htim1, &sMasterConfig) != HAL_OK)
  {
    Error_Handler();
  }

}

static void MX_TIM2_Init(void)
{

  TIM_ClockConfigTypeDef sClockSourceConfig = {0};
  TIM_MasterConfigTypeDef sMasterConfig = {0};
  TIM_OC_InitTypeDef sConfigOC = {0};

  htim2.Instance = TIM2;
  htim2.Init.Prescaler = 0;
  htim2.Init.CounterMode = TIM_COUNTERMODE_CENTERALIGNED3;
  htim2.Init.Period = 1699;
  htim2.Init.ClockDivision = TIM_CLOCKDIVISION_DIV1;
  htim2.Init.AutoReloadPreload = TIM_AUTORELOAD_PRELOAD_DISABLE;
  if (HAL_TIM_Base_Init(&htim2) != HAL_OK)
  {
    Error_Handler();
  }
  HAL_TIMEx_DitheringEnable(&htim2);

  /* rewrite ARR register when dither mode active */
  __HAL_TIM_SET_AUTORELOAD(&htim2, 27199);
  HAL_TIM_GenerateEvent(&htim2, TIM_EVENTSOURCE_UPDATE);
  sClockSourceConfig.ClockSource = TIM_CLOCKSOURCE_INTERNAL;
  if (HAL_TIM_ConfigClockSource(&htim2, &sClockSourceConfig) != HAL_OK)
  {
    Error_Handler();
  }
  if (HAL_TIM_PWM_Init(&htim2) != HAL_OK)
  {
    Error_Handler();
  }
  sMasterConfig.MasterOutputTrigger = TIM_TRGO_UPDATE;
  sMasterConfig.MasterSlaveMode = TIM_MASTERSLAVEMODE_DISABLE;
  if (HAL_TIMEx_MasterConfigSynchronization(&htim2, &sMasterConfig) != HAL_OK)
  {
    Error_Handler();
  }
  sConfigOC.OCMode = TIM_OCMODE_PWM1;
  sConfigOC.Pulse = 0;
  sConfigOC.OCPolarity = TIM_OCPOLARITY_HIGH;
  sConfigOC.OCFastMode = TIM_OCFAST_DISABLE;
  if (HAL_TIM_PWM_ConfigChannel(&htim2, &sConfigOC, TIM_CHANNEL_1) != HAL_OK)
  {
    Error_Handler();
  }
  if (HAL_TIM_PWM_ConfigChannel(&htim2, &sConfigOC, TIM_CHANNEL_2) != HAL_OK)
  {
    Error_Handler();
  }
  if (HAL_TIM_PWM_ConfigChannel(&htim2, &sConfigOC, TIM_CHANNEL_3) != HAL_OK)
  {
    Error_Handler();
  }
  if (HAL_TIM_PWM_ConfigChannel(&htim2, &sConfigOC, TIM_CHANNEL_4) != HAL_OK)
  {
    Error_Handler();
  }
  HAL_TIM_MspPostInit(&htim2);

}

static void MX_TIM3_Init(void)
{

  TIM_Encoder_InitTypeDef sConfig = {0};
  TIM_MasterConfigTypeDef sMasterConfig = {0};
  TIMEx_EncoderIndexConfigTypeDef sEncoderIndexConfig = {0};

  htim3.Instance = TIM3;
  htim3.Init.Prescaler = 0;
  htim3.Init.CounterMode = TIM_COUNTERMODE_UP;
  htim3.Init.Period = 65535;
  htim3.Init.ClockDivision = TIM_CLOCKDIVISION_DIV1;
  htim3.Init.AutoReloadPreload = TIM_AUTORELOAD_PRELOAD_DISABLE;
  sConfig.EncoderMode = TIM_ENCODERMODE_TI1;
  sConfig.IC1Polarity = TIM_ICPOLARITY_RISING;
  sConfig.IC1Selection = TIM_ICSELECTION_DIRECTTI;
  sConfig.IC1Prescaler = TIM_ICPSC_DIV1;
  sConfig.IC1Filter = 0;
  sConfig.IC2Polarity = TIM_ICPOLARITY_RISING;
  sConfig.IC2Selection = TIM_ICSELECTION_DIRECTTI;
  sConfig.IC2Prescaler = TIM_ICPSC_DIV1;
  sConfig.IC2Filter = 0;
  if (HAL_TIM_Encoder_Init(&htim3, &sConfig) != HAL_OK)
  {
    Error_Handler();
  }
  sMasterConfig.MasterOutputTrigger = TIM_TRGO_RESET;
  sMasterConfig.MasterSlaveMode = TIM_MASTERSLAVEMODE_DISABLE;
  if (HAL_TIMEx_MasterConfigSynchronization(&htim3, &sMasterConfig) != HAL_OK)
  {
    Error_Handler();
  }
  sEncoderIndexConfig.Polarity = TIM_ENCODERINDEX_POLARITY_NONINVERTED;
  sEncoderIndexConfig.Prescaler = TIM_ENCODERINDEX_PRESCALER_DIV1;
  sEncoderIndexConfig.Filter = 0;
  sEncoderIndexConfig.FirstIndexEnable = DISABLE;
  sEncoderIndexConfig.Position = TIM_ENCODERINDEX_POSITION_00;
  sEncoderIndexConfig.Direction = TIM_ENCODERINDEX_DIRECTION_UP_DOWN;
  if (HAL_TIMEx_ConfigEncoderIndex(&htim3, &sEncoderIndexConfig) != HAL_OK)
  {
    Error_Handler();
  }

}

static void MX_TIM4_Init(void)
{

  TIM_ClockConfigTypeDef sClockSourceConfig = {0};
  TIM_MasterConfigTypeDef sMasterConfig = {0};
  TIM_OC_InitTypeDef sConfigOC = {0};

  htim4.Instance = TIM4;
  htim4.Init.Prescaler = 0;
  htim4.Init.CounterMode = TIM_COUNTERMODE_UP;
  htim4.Init.Period = 65535;
  htim4.Init.ClockDivision = TIM_CLOCKDIVISION_DIV1;
  htim4.Init.AutoReloadPreload = TIM_AUTORELOAD_PRELOAD_DISABLE;
  if (HAL_TIM_Base_Init(&htim4) != HAL_OK)
  {
    Error_Handler();
  }
  sClockSourceConfig.ClockSource = TIM_CLOCKSOURCE_INTERNAL;
  if (HAL_TIM_ConfigClockSource(&htim4, &sClockSourceConfig) != HAL_OK)
  {
    Error_Handler();
  }
  if (HAL_TIM_PWM_Init(&htim4) != HAL_OK)
  {
    Error_Handler();
  }
  sMasterConfig.MasterOutputTrigger = TIM_TRGO_RESET;
  sMasterConfig.MasterSlaveMode = TIM_MASTERSLAVEMODE_DISABLE;
  if (HAL_TIMEx_MasterConfigSynchronization(&htim4, &sMasterConfig) != HAL_OK)
  {
    Error_Handler();
  }
  sConfigOC.OCMode = TIM_OCMODE_PWM1;
  sConfigOC.Pulse = 0;
  sConfigOC.OCPolarity = TIM_OCPOLARITY_HIGH;
  sConfigOC.OCFastMode = TIM_OCFAST_DISABLE;
  if (HAL_TIM_PWM_ConfigChannel(&htim4, &sConfigOC, TIM_CHANNEL_1) != HAL_OK)
  {
    Error_Handler();
  }
  if (HAL_TIM_PWM_ConfigChannel(&htim4, &sConfigOC, TIM_CHANNEL_2) != HAL_OK)
  {
    Error_Handler();
  }
  if (HAL_TIM_PWM_ConfigChannel(&htim4, &sConfigOC, TIM_CHANNEL_3) != HAL_OK)
  {
    Error_Handler();
  }
  if (HAL_TIM_PWM_ConfigChannel(&htim4, &sConfigOC, TIM_CHANNEL_4) != HAL_OK)
  {
    Error_Handler();
  }
  HAL_TIM_MspPostInit(&htim4);

}

static void MX_TIM6_Init(void)
{

  TIM_MasterConfigTypeDef sMasterConfig = {0};

  htim6.Instance = TIM6;
  htim6.Init.Prescaler = 169;
  htim6.Init.CounterMode = TIM_COUNTERMODE_UP;
  htim6.Init.Period = 65535;
  htim6.Init.AutoReloadPreload = TIM_AUTORELOAD_PRELOAD_DISABLE;
  if (HAL_TIM_Base_Init(&htim6) != HAL_OK)
  {
    Error_Handler();
  }
  sMasterConfig.MasterOutputTrigger = TIM_TRGO_RESET;
  sMasterConfig.MasterSlaveMode = TIM_MASTERSLAVEMODE_DISABLE;
  if (HAL_TIMEx_MasterConfigSynchronization(&htim6, &sMasterConfig) != HAL_OK)
  {
    Error_Handler();
  }

}

static void MX_TIM15_Init(void)
{

  TIM_ClockConfigTypeDef sClockSourceConfig = {0};
  TIM_SlaveConfigTypeDef sSlaveConfig = {0};
  TIM_MasterConfigTypeDef sMasterConfig = {0};
  TIM_OC_InitTypeDef sConfigOC = {0};
  TIM_BreakDeadTimeConfigTypeDef sBreakDeadTimeConfig = {0};

  htim15.Instance = TIM15;
  htim15.Init.Prescaler = 0;
  htim15.Init.CounterMode = TIM_COUNTERMODE_UP;
  htim15.Init.Period = 1699;
  htim15.Init.ClockDivision = TIM_CLOCKDIVISION_DIV1;
  htim15.Init.RepetitionCounter = 0;
  htim15.Init.AutoReloadPreload = TIM_AUTORELOAD_PRELOAD_DISABLE;
  if (HAL_TIM_Base_Init(&htim15) != HAL_OK)
  {
    Error_Handler();
  }
  sClockSourceConfig.ClockSource = TIM_CLOCKSOURCE_INTERNAL;
  if (HAL_TIM_ConfigClockSource(&htim15, &sClockSourceConfig) != HAL_OK)
  {
    Error_Handler();
  }
  if (HAL_TIM_OC_Init(&htim15) != HAL_OK)
  {
    Error_Handler();
  }
  if (HAL_TIM_OnePulse_Init(&htim15, TIM_OPMODE_SINGLE) != HAL_OK)
  {
    Error_Handler();
  }
  sSlaveConfig.SlaveMode = TIM_SLAVEMODE_COMBINED_RESETTRIGGER;
  sSlaveConfig.InputTrigger = TIM_TS_ITR1;
  if (HAL_TIM_SlaveConfigSynchro(&htim15, &sSlaveConfig) != HAL_OK)
  {
    Error_Handler();
  }
  sMasterConfig.MasterOutputTrigger = TIM_TRGO_OC1;
  sMasterConfig.MasterSlaveMode = TIM_MASTERSLAVEMODE_DISABLE;
  if (HAL_TIMEx_MasterConfigSynchronization(&htim15, &sMasterConfig) != HAL_OK)
  {
    Error_Handler();
  }
  sConfigOC.OCMode = TIM_OCMODE_ACTIVE;
  sConfigOC.Pulse = 1099;
  sConfigOC.OCPolarity = TIM_OCPOLARITY_HIGH;
  sConfigOC.OCNPolarity = TIM_OCNPOLARITY_HIGH;
  sConfigOC.OCFastMode = TIM_OCFAST_DISABLE;
  sConfigOC.OCIdleState = TIM_OCIDLESTATE_RESET;
  sConfigOC.OCNIdleState = TIM_OCNIDLESTATE_RESET;
  if (HAL_TIM_OC_ConfigChannel(&htim15, &sConfigOC, TIM_CHANNEL_1) != HAL_OK)
  {
    Error_Handler();
  }
  __HAL_TIM_ENABLE_OCxPRELOAD(&htim15, TIM_CHANNEL_1);
  sBreakDeadTimeConfig.OffStateRunMode = TIM_OSSR_DISABLE;
  sBreakDeadTimeConfig.OffStateIDLEMode = TIM_OSSI_DISABLE;
  sBreakDeadTimeConfig.LockLevel = TIM_LOCKLEVEL_OFF;
  sBreakDeadTimeConfig.DeadTime = 0;
  sBreakDeadTimeConfig.BreakState = TIM_BREAK_DISABLE;
  sBreakDeadTimeConfig.BreakPolarity = TIM_BREAKPOLARITY_HIGH;
  sBreakDeadTimeConfig.BreakFilter = 0;
  sBreakDeadTimeConfig.AutomaticOutput = TIM_AUTOMATICOUTPUT_DISABLE;
  if (HAL_TIMEx_ConfigBreakDeadTime(&htim15, &sBreakDeadTimeConfig) != HAL_OK)
  {
    Error_Handler();
  }

}

static void MX_TIM16_Init(void)
{

  TIM_OC_InitTypeDef sConfigOC = {0};
  TIM_BreakDeadTimeConfigTypeDef sBreakDeadTimeConfig = {0};

  htim16.Instance = TIM16;
  htim16.Init.Prescaler = 0;
  htim16.Init.CounterMode = TIM_COUNTERMODE_UP;
  htim16.Init.Period = 1699;
  htim16.Init.ClockDivision = TIM_CLOCKDIVISION_DIV1;
  htim16.Init.RepetitionCounter = 0;
  htim16.Init.AutoReloadPreload = TIM_AUTORELOAD_PRELOAD_DISABLE;
  if (HAL_TIM_Base_Init(&htim16) != HAL_OK)
  {
    Error_Handler();
  }
  if (HAL_TIM_OC_Init(&htim16) != HAL_OK)
  {
    Error_Handler();
  }
  if (HAL_TIM_OnePulse_Init(&htim16, TIM_OPMODE_SINGLE) != HAL_OK)
  {
    Error_Handler();
  }
  sConfigOC.OCMode = TIM_OCMODE_TIMING;
  sConfigOC.Pulse = 65535;
  sConfigOC.OCPolarity = TIM_OCPOLARITY_HIGH;
  sConfigOC.OCNPolarity = TIM_OCNPOLARITY_HIGH;
  sConfigOC.OCFastMode = TIM_OCFAST_DISABLE;
  sConfigOC.OCIdleState = TIM_OCIDLESTATE_RESET;
  sConfigOC.OCNIdleState = TIM_OCNIDLESTATE_RESET;
  if (HAL_TIM_OC_ConfigChannel(&htim16, &sConfigOC, TIM_CHANNEL_1) != HAL_OK)
  {
    Error_Handler();
  }
  __HAL_TIM_ENABLE_OCxPRELOAD(&htim16, TIM_CHANNEL_1);
  sBreakDeadTimeConfig.OffStateRunMode = TIM_OSSR_DISABLE;
  sBreakDeadTimeConfig.OffStateIDLEMode = TIM_OSSI_DISABLE;
  sBreakDeadTimeConfig.LockLevel = TIM_LOCKLEVEL_OFF;
  sBreakDeadTimeConfig.DeadTime = 0;
  sBreakDeadTimeConfig.BreakState = TIM_BREAK_DISABLE;
  sBreakDeadTimeConfig.BreakPolarity = TIM_BREAKPOLARITY_HIGH;
  sBreakDeadTimeConfig.BreakFilter = 0;
  sBreakDeadTimeConfig.AutomaticOutput = TIM_AUTOMATICOUTPUT_DISABLE;
  if (HAL_TIMEx_ConfigBreakDeadTime(&htim16, &sBreakDeadTimeConfig) != HAL_OK)
  {
    Error_Handler();
  }

}

static void MX_USART1_UART_Init(void)
{

  huart1.Instance = USART1;
  huart1.Init.BaudRate = 115200;
  huart1.Init.WordLength = UART_WORDLENGTH_8B;
  huart1.Init.StopBits = UART_STOPBITS_1;
  huart1.Init.Parity = UART_PARITY_NONE;
  huart1.Init.Mode = UART_MODE_TX_RX;
  huart1.Init.HwFlowCtl = UART_HWCONTROL_NONE;
  huart1.Init.OverSampling = UART_OVERSAMPLING_16;
  huart1.Init.OneBitSampling = UART_ONE_BIT_SAMPLE_DISABLE;
  huart1.Init.ClockPrescaler = UART_PRESCALER_DIV1;
  huart1.AdvancedInit.AdvFeatureInit = UART_ADVFEATURE_NO_INIT;
  if (HAL_UART_Init(&huart1) != HAL_OK)
  {
    Error_Handler();
  }
  if (HAL_UARTEx_SetTxFifoThreshold(&huart1, UART_TXFIFO_THRESHOLD_1_8) != HAL_OK)
  {
    Error_Handler();
  }
  if (HAL_UARTEx_SetRxFifoThreshold(&huart1, UART_RXFIFO_THRESHOLD_1_8) != HAL_OK)
  {
    Error_Handler();
  }
  if (HAL_UARTEx_DisableFifoMode(&huart1) != HAL_OK)
  {
    Error_Handler();
  }

}

static void MX_USB_PCD_Init(void)
{

  /* USER CODE BEGIN USB_Init 0 */

#if 0 // disable USB code as we use USBDevice instead

  /* USER CODE END USB_Init 0 */

  hpcd_USB_FS.Instance = USB;
  hpcd_USB_FS.Init.dev_endpoints = 8;
  hpcd_USB_FS.Init.speed = PCD_SPEED_FULL;
  hpcd_USB_FS.Init.phy_itface = PCD_PHY_EMBEDDED;
  hpcd_USB_FS.Init.Sof_enable = ENABLE;
  hpcd_USB_FS.Init.low_power_enable = DISABLE;
  hpcd_USB_FS.Init.lpm_enable = ENABLE;
  hpcd_USB_FS.Init.battery_charging_enable = DISABLE;
  if (HAL_PCD_Init(&hpcd_USB_FS) != HAL_OK)
  {
    Error_Handler();
  }
  /* USER CODE BEGIN USB_Init 2 */

#endif // 0

  /* USER CODE END USB_Init 2 */

}

static void MX_DMA_Init(void)
{

  /* DMA controller clock enable */
  __HAL_RCC_DMAMUX1_CLK_ENABLE();
  __HAL_RCC_DMA2_CLK_ENABLE();
  __HAL_RCC_DMA1_CLK_ENABLE();

  /* DMA interrupt init */
  /* DMA1_Channel1_IRQn interrupt configuration */
  HAL_NVIC_SetPriority(DMA1_Channel1_IRQn, 1, 0);
  HAL_NVIC_EnableIRQ(DMA1_Channel1_IRQn);
  /* DMA1_Channel2_IRQn interrupt configuration */
  HAL_NVIC_SetPriority(DMA1_Channel2_IRQn, 1, 0);
  HAL_NVIC_EnableIRQ(DMA1_Channel2_IRQn);
  /* DMA2_Channel1_IRQn interrupt configuration */
  HAL_NVIC_SetPriority(DMA2_Channel1_IRQn, 2, 0);
  HAL_NVIC_EnableIRQ(DMA2_Channel1_IRQn);
  /* DMA2_Channel2_IRQn interrupt configuration */
  HAL_NVIC_SetPriority(DMA2_Channel2_IRQn, 2, 0);
  HAL_NVIC_EnableIRQ(DMA2_Channel2_IRQn);

}

static void MX_GPIO_Init(void)
{
  GPIO_InitTypeDef GPIO_InitStruct = {0};

  /* GPIO Ports Clock Enable */
  __HAL_RCC_GPIOF_CLK_ENABLE();
  __HAL_RCC_GPIOA_CLK_ENABLE();
  __HAL_RCC_GPIOC_CLK_ENABLE();
  __HAL_RCC_GPIOB_CLK_ENABLE();

  /*Configure GPIO pin Output Level */
  HAL_GPIO_WritePin(GPIOA, GPIO_PIN_7, GPIO_PIN_RESET);

  /*Configure GPIO pin Output Level */
  HAL_GPIO_WritePin(GPIOB, GPIO_PIN_0|GPIO_PIN_1|GPIO_PIN_2, GPIO_PIN_RESET);

  /*Configure GPIO pin Output Level */
  HAL_GPIO_WritePin(GPIOB, GPIO_PIN_10, GPIO_PIN_SET);

  /*Configure GPIO pin Output Level */
  HAL_GPIO_WritePin(GPIOC, GPIO_PIN_6, GPIO_PIN_SET);

  /*Configure GPIO pin : PA7 */
  GPIO_InitStruct.Pin = GPIO_PIN_7;
  GPIO_InitStruct.Mode = GPIO_MODE_OUTPUT_PP;
  GPIO_InitStruct.Pull = GPIO_NOPULL;
  GPIO_InitStruct.Speed = GPIO_SPEED_FREQ_VERY_HIGH;
  HAL_GPIO_Init(GPIOA, &GPIO_InitStruct);

  /*Configure GPIO pin : PC4 */
  GPIO_InitStruct.Pin = GPIO_PIN_4;
  GPIO_InitStruct.Mode = GPIO_MODE_INPUT;
  GPIO_InitStruct.Pull = GPIO_PULLUP;
  HAL_GPIO_Init(GPIOC, &GPIO_InitStruct);

  /*Configure GPIO pins : PB0 PB1 PB2 PB10 */
  GPIO_InitStruct.Pin = GPIO_PIN_0|GPIO_PIN_1|GPIO_PIN_2|GPIO_PIN_10;
  GPIO_InitStruct.Mode = GPIO_MODE_OUTPUT_PP;
  GPIO_InitStruct.Pull = GPIO_NOPULL;
  GPIO_InitStruct.Speed = GPIO_SPEED_FREQ_VERY_HIGH;
  HAL_GPIO_Init(GPIOB, &GPIO_InitStruct);

  /*Configure GPIO pin : PC6 */
  GPIO_InitStruct.Pin = GPIO_PIN_6;
  GPIO_InitStruct.Mode = GPIO_MODE_OUTPUT_PP;
  GPIO_InitStruct.Pull = GPIO_NOPULL;
  GPIO_InitStruct.Speed = GPIO_SPEED_FREQ_VERY_HIGH;
  HAL_GPIO_Init(GPIOC, &GPIO_InitStruct);

}

void Error_Handler(void)
{
}
